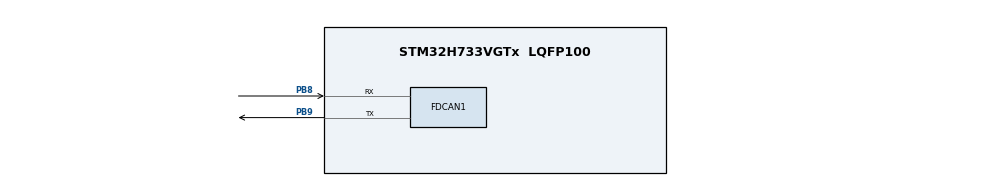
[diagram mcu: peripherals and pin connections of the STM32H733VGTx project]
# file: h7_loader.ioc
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CORTEX_M7.default_mode_Activation=0
CRC.InputDataFormat=CRC_INPUTDATA_FORMAT_WORDS
FDCAN1.AutoRetransmission=ENABLE
FDCAN1.CalculateBaudRateNominal=500000
FDCAN1.CalculateTimeBitNominal=2000
FDCAN1.CalculateTimeQuantumNominal=125.0
FDCAN1.NominalPrescaler=6
FDCAN1.NominalSyncJumpWidth=4
FDCAN1.NominalTimeSeg1=13
FDCAN1.RxFifo0ElmtsNbr=1
FDCAN1.StdFiltersNbr=1
FDCAN1.TxFifoQueueElmtsNbr=1
FREERTOS.Tasks01=defaultTask,24,1024,StartDefaultTask,Default,NULL,Dynamic,NULL,NULL
FREERTOS.configMINIMAL_STACK_SIZE=128
Mcu.Family=STM32H7
Mcu.Name=STM32H733VGTx
Mcu.Package=LQFP100
Mcu.UserConstants=TIM3_PRESCALER,8;ADC_FREQUENCY,1000;TIMx_FREQUENCY,512000000
NVIC.FDCAN1_IT0_IRQn=true\:5\:0\:false\:false\:true\:true\:true\:true\:true
NVIC.FDCAN1_IT1_IRQn=true\:5\:0\:false\:false\:true\:true\:true\:true\:true
NVIC.PriorityGroup=NVIC_PRIORITYGROUP_4
NVIC.TIM6_DAC_IRQn=true\:15\:0\:false\:false\:true\:false\:false\:true\:true
NVIC.TimeBase=TIM6_DAC_IRQn
NVIC.TimeBaseIP=TIM6
PB8.Mode=FDCAN_Activate
PB8.Signal=FDCAN1_RX
PB9.Mode=FDCAN_Activate
PB9.Signal=FDCAN1_TX
PH0-OSC_IN.Mode=HSE-External-Oscillator
PH0-OSC_IN.Signal=RCC_OSC_IN
PH1-OSC_OUT.Mode=HSE-External-Oscillator
PH1-OSC_OUT.Signal=RCC_OSC_OUT
ProjectManager.HeapSize=0x200
ProjectManager.StackSize=0x400
ProjectManager.TargetToolchain=STM32CubeIDE
RCC.ADCFreq_Value=16125000
RCC.APB1Freq_Value=24000000
RCC.APB2Freq_Value=24000000
RCC.APB3Freq_Value=24000000
RCC.APB4Freq_Value=24000000
RCC.CortexFreq_Value=96000000
RCC.D1CPRE=RCC_SYSCLK_DIV2
RCC.D1PPRE=RCC_APB3_DIV2
RCC.D2PPRE1=RCC_APB1_DIV2
RCC.D2PPRE2=RCC_APB2_DIV2
RCC.D3PPRE=RCC_APB4_DIV2
RCC.DIVM1=1
RCC.DIVN1=24
RCC.DIVP1=1
RCC.DIVQ1=4
RCC.HCLKFreq_Value=48000000
RCC.HPRE=RCC_HCLK_DIV2
RCC.HSE_VALUE=8000000
RCC.PLL2FRACN=0
RCC.PLL3FRACN=0
RCC.PLLFRACN=0
RCC.PLLSourceVirtual=RCC_PLLSOURCE_HSE
RCC.SYSCLKFreq_VALUE=192000000
RCC.SYSCLKSource=RCC_SYSCLKSOURCE_PLLCLK
RCC.USBFreq_Value=48000000
VP_CRC_VS_CRC.Mode=CRC_Activate
VP_FREERTOS_VS_CMSIS_V2.Mode=CMSIS_V2
VP_SYS_VS_tim6.Mode=TIM6
board=custom

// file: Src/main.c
/* USER CODE BEGIN Header */
/**
 ******************************************************************************
 * @file           : main.c
 * @brief          : Main program body
 ******************************************************************************
 * @attention
 *
 * Copyright (c) 2024 STMicroelectronics.
 * All rights reserved.
 *
 * This software is licensed under terms that can be found in the LICENSE file
 * in the root directory of this software component.
 * If no LICENSE file comes with this software, it is provided AS-IS.
 *
 ******************************************************************************
 */
/* USER CODE END Header */
#include "main.h"
#include "cmsis_os.h"

/* USER CODE BEGIN Includes */
#include "cmsis_gcc.h"
#include "hw_crc.h"
#include "hw_hal.h"
#include "hw_hardFaultHandler.h"
#include "hw_utils.h"
#include "hw_can.h"

#include "io_can.h"
/* USER CODE END Includes */

/* USER CODE BEGIN PD */
extern uint32_t __app_metadata_start__;
extern uint32_t __app_metadata_size__;

extern uint32_t __app_code_start__;
extern uint32_t __app_code_size__;

extern uint32_t __boot_code_start__;
extern uint32_t __boot_code_size__;

__attribute__((section(".boot_flag"))) uint8_t boot_flag;

typedef enum
{
    LOADER_STATUS_APP_VALID,
    LOADER_STATUS_APP_INVALID,
    LOADER_STATUS_NO_APP
} LoaderStatus;

typedef struct
{
    uint32_t checksum;
    uint32_t size_bytes;
    uint32_t bootloader_status;
} Metadata;
/* USER CODE END PD */

CRC_HandleTypeDef hcrc;

FDCAN_HandleTypeDef hfdcan1;

/* Definitions for defaultTask */
osThreadId_t         defaultTaskHandle;
const osThreadAttr_t defaultTask_attributes = {
    .name       = "defaultTask",
    .stack_size = 1024 * 4,
    .priority   = (osPriority_t)osPriorityNormal,
};
/* USER CODE BEGIN PV */
static void canRxOverflow(uint32_t unused)
{
    UNUSED(unused);
    // BREAK_IF_DEBUGGER_CONNECTED();
}

static void canTxOverflow(uint32_t unused)
{
    UNUSED(unused);
    // BREAK_IF_DEBUGGER_CONNECTED();
}

static const CanConfig can_config = {
    .rx_msg_filter        = NULL,
    .rx_overflow_callback = canRxOverflow,
    .tx_overflow_callback = canTxOverflow,
};

CanHandle can = {
    .can                       = &hfdcan1,
    .can_msg_received_callback = io_can_pushRxMsgToQueue,
};

static LoaderStatus verifyAppCodeChecksum(void)
{
    if (*&__app_code_start__ == 0xFFFFFFFF)
    {
        // If app initial stack pointer is all 0xFF, assume app is not present.
        return LOADER_STATUS_NO_APP;
    }

    Metadata *metadata = (Metadata *)&__app_metadata_start__;
    if (metadata->size_bytes > (uint32_t)&__app_code_size__)
    {
        // App binary size field is invalid.
        return LOADER_STATUS_APP_INVALID;
    }

    uint32_t *buffer              = &__app_code_start__;
    uint32_t  calculated_checksum = hw_crc_calculate(&__app_code_start__, metadata->size_bytes / 4);
    return calculated_checksum == metadata->checksum ? LOADER_STATUS_APP_VALID : LOADER_STATUS_APP_INVALID;
}

_Noreturn static void modifyStackPointerAndJump(const uint32_t *address)
{
    // Disable interrupts before jumping.
    __disable_irq();

    // Disable system tick to stop FreeRTOS timebase.
    SysTick->CTRL = ~SysTick_CTRL_ENABLE_Msk;

    // Clear all pending interrupts by setting all ICPRs (Interrupt Clear Pending Register)
    // to 0xFFFFFFFF. This is done so no interrupts are queued up when we jump to the app.
    // (There are 8 registers on the Cortex-M4)
    for (uint32_t i = 0; i < 8; i++)
    {
        NVIC->ICPR[i] = 0xFFFFFFFF;
    }

    // Update the vector table offset register. When an interrupt is fired,
    // the microcontroller looks for the corresponding interrupt service handler
    // at the memory address in the VTOR. We need to update it so the app ISRs
    // are used.
    SCB->VTOR = (uint32_t)address;

    // Flush processor pipeline.
    __ISB();

    // Tell MCU to use the main stack pointer rather than process stack pointer (PSP is used with RTOS)
    __set_CONTROL(__get_CONTROL() & ~CONTROL_SPSEL_Msk);

    // Modify stack pointer and jump to code.
    // In a binary built with our linker settings, the interrupt vector table is the first thing
    // placed in flash. The first word of the vector table contains the initial stack pointer
    // and the second word containers the address of the reset handler. Update stack pointer and
    // program counter accordingly.
#pragma GCC diagnostic push
#pragma GCC diagnostic ignored "-Warray-bounds"
    uint32_t newStackPointer = address[0];
    uint32_t resetHandler    = address[1];
#pragma GCC diagnostic pop
    __set_MSP(newStackPointer);
    void (*app_reset_handler)(void) = (void (*)(void))resetHandler;
    app_reset_handler(); // Call app's Reset_Handler, starting the app.

    // Should never get here!
    BREAK_IF_DEBUGGER_CONNECTED();
    for (;;)
    {
    }
}
/* USER CODE END PV */

void        SystemClock_Config(void);
static void MX_GPIO_Init(void);
static void MX_CRC_Init(void);
static void MX_FDCAN1_Init(void);
void        StartDefaultTask(void *argument);

int main(void)
{
    /* USER CODE BEGIN 1 */
    // SEGGER_SYSVIEW_Conf();
    /* USER CODE END 1 */

    /* MCU Configuration--------------------------------------------------------*/

    /* Reset of all peripherals, Initializes the Flash interface and the Systick. */
    HAL_Init();

    /* Configure the system clock */
    SystemClock_Config();

    /* USER CODE BEGIN SysInit */
    __HAL_RCC_CRC_CLK_ENABLE();
    __HAL_RCC_FDCAN_CLK_ENABLE();
    /* USER CODE END SysInit */

    /* Initialize all configured peripherals */
    MX_GPIO_Init();
    MX_CRC_Init();
    MX_FDCAN1_Init();
    /* USER CODE BEGIN 2 */

    hw_hardFaultHandler_init();
    hw_crc_init(&hcrc);
    io_can_init(&can_config);
    hw_can_init(&can);

    LoaderStatus status = verifyAppCodeChecksum();
    HAL_CRC_DeInit(&hcrc);
    if (status == LOADER_STATUS_APP_INVALID || boot_flag == 0x01)
    {
        modifyStackPointerAndJump(&__boot_code_start__);
    }
    else
    {
        modifyStackPointerAndJump(&__app_code_start__);
    }
    /* USER CODE END 2 */

    /* Init scheduler */
    osKernelInitialize();

    /* Create the thread(s) */
    /* creation of defaultTask */
    defaultTaskHandle = osThreadNew(StartDefaultTask, NULL, &defaultTask_attributes);

    /* Start scheduler */
    osKernelStart();

    /* We should never get here as control is now taken by the scheduler */
    /* Infinite loop */
    while (1)
    {

    }
}

void SystemClock_Config(void)
{
    RCC_OscInitTypeDef RCC_OscInitStruct = { 0 };
    RCC_ClkInitTypeDef RCC_ClkInitStruct = { 0 };

    /** Supply configuration update enable
     */
    HAL_PWREx_ConfigSupply(PWR_LDO_SUPPLY);

    /** Configure the main internal regulator output voltage
     */
    __HAL_PWR_VOLTAGESCALING_CONFIG(PWR_REGULATOR_VOLTAGE_SCALE3);

    while (!__HAL_PWR_GET_FLAG(PWR_FLAG_VOSRDY))
    {
    }

    /** Initializes the RCC Oscillators according to the specified parameters
     * in the RCC_OscInitTypeDef structure.
     */
    RCC_OscInitStruct.OscillatorType = RCC_OSCILLATORTYPE_HSE;
    RCC_OscInitStruct.HSEState       = RCC_HSE_ON;
    RCC_OscInitStruct.PLL.PLLState   = RCC_PLL_ON;
    RCC_OscInitStruct.PLL.PLLSource  = RCC_PLLSOURCE_HSE;
    RCC_OscInitStruct.PLL.PLLM       = 1;
    RCC_OscInitStruct.PLL.PLLN       = 24;
    RCC_OscInitStruct.PLL.PLLP       = 1;
    RCC_OscInitStruct.PLL.PLLQ       = 4;
    RCC_OscInitStruct.PLL.PLLR       = 2;
    RCC_OscInitStruct.PLL.PLLRGE     = RCC_PLL1VCIRANGE_3;
    RCC_OscInitStruct.PLL.PLLVCOSEL  = RCC_PLL1VCOWIDE;
    RCC_OscInitStruct.PLL.PLLFRACN   = 0;
    if (HAL_RCC_OscConfig(&RCC_OscInitStruct) != HAL_OK)
    {
        Error_Handler();
    }

    /** Initializes the CPU, AHB and APB buses clocks
     */
    RCC_ClkInitStruct.ClockType = RCC_CLOCKTYPE_HCLK | RCC_CLOCKTYPE_SYSCLK | RCC_CLOCKTYPE_PCLK1 |
                                  RCC_CLOCKTYPE_PCLK2 | RCC_CLOCKTYPE_D3PCLK1 | RCC_CLOCKTYPE_D1PCLK1;
    RCC_ClkInitStruct.SYSCLKSource   = RCC_SYSCLKSOURCE_PLLCLK;
    RCC_ClkInitStruct.SYSCLKDivider  = RCC_SYSCLK_DIV2;
    RCC_ClkInitStruct.AHBCLKDivider  = RCC_HCLK_DIV2;
    RCC_ClkInitStruct.APB3CLKDivider = RCC_APB3_DIV2;
    RCC_ClkInitStruct.APB1CLKDivider = RCC_APB1_DIV2;
    RCC_ClkInitStruct.APB2CLKDivider = RCC_APB2_DIV2;
    RCC_ClkInitStruct.APB4CLKDivider = RCC_APB4_DIV2;

    if (HAL_RCC_ClockConfig(&RCC_ClkInitStruct, FLASH_LATENCY_1) != HAL_OK)
    {
        Error_Handler();
    }
}

static void MX_CRC_Init(void)
{

    hcrc.Instance                     = CRC;
    hcrc.Init.DefaultPolynomialUse    = DEFAULT_POLYNOMIAL_ENABLE;
    hcrc.Init.DefaultInitValueUse     = DEFAULT_INIT_VALUE_ENABLE;
    hcrc.Init.InputDataInversionMode  = CRC_INPUTDATA_INVERSION_NONE;
    hcrc.Init.OutputDataInversionMode = CRC_OUTPUTDATA_INVERSION_DISABLE;
    hcrc.InputDataFormat              = CRC_INPUTDATA_FORMAT_WORDS;
    if (HAL_CRC_Init(&hcrc) != HAL_OK)
    {
        Error_Handler();
    }
    /* USER CODE BEGIN CRC_Init 2 */
    uint32_t test_data[] = { 0x12345678, 0x9ABCDEF0 };
    size_t   test_length = sizeof(test_data) / sizeof(test_data[0]);
    uint32_t test_crc    = HAL_CRC_Calculate(&hcrc, test_data, test_length);
    /* USER CODE END CRC_Init 2 */
}

static void MX_FDCAN1_Init(void)
{

    hfdcan1.Instance                  = FDCAN1;
    hfdcan1.Init.FrameFormat          = FDCAN_FRAME_CLASSIC;
    hfdcan1.Init.Mode                 = FDCAN_MODE_NORMAL;
    hfdcan1.Init.AutoRetransmission   = ENABLE;
    hfdcan1.Init.TransmitPause        = DISABLE;
    hfdcan1.Init.ProtocolException    = DISABLE;
    hfdcan1.Init.NominalPrescaler     = 6;
    hfdcan1.Init.NominalSyncJumpWidth = 4;
    hfdcan1.Init.NominalTimeSeg1      = 13;
    hfdcan1.Init.NominalTimeSeg2      = 2;
    hfdcan1.Init.DataPrescaler        = 1;
    hfdcan1.Init.DataSyncJumpWidth    = 1;
    hfdcan1.Init.DataTimeSeg1         = 1;
    hfdcan1.Init.DataTimeSeg2         = 1;
    hfdcan1.Init.MessageRAMOffset     = 0;
    hfdcan1.Init.StdFiltersNbr        = 1;
    hfdcan1.Init.ExtFiltersNbr        = 0;
    hfdcan1.Init.RxFifo0ElmtsNbr      = 1;
    hfdcan1.Init.RxFifo0ElmtSize      = FDCAN_DATA_BYTES_8;
    hfdcan1.Init.RxFifo1ElmtsNbr      = 0;
    hfdcan1.Init.RxFifo1ElmtSize      = FDCAN_DATA_BYTES_8;
    hfdcan1.Init.RxBuffersNbr         = 0;
    hfdcan1.Init.RxBufferSize         = FDCAN_DATA_BYTES_8;
    hfdcan1.Init.TxEventsNbr          = 0;
    hfdcan1.Init.TxBuffersNbr         = 0;
    hfdcan1.Init.TxFifoQueueElmtsNbr  = 1;
    hfdcan1.Init.TxFifoQueueMode      = FDCAN_TX_FIFO_OPERATION;
    hfdcan1.Init.TxElmtSize           = FDCAN_DATA_BYTES_8;
    if (HAL_FDCAN_Init(&hfdcan1) != HAL_OK)
    {
        Error_Handler();
    }
}

static void MX_GPIO_Init(void)
{

    /* GPIO Ports Clock Enable */
    __HAL_RCC_GPIOH_CLK_ENABLE();
    __HAL_RCC_GPIOB_CLK_ENABLE();

}

void StartDefaultTask(void *argument)
{
}

void HAL_TIM_PeriodElapsedCallback(TIM_HandleTypeDef *htim)
{
    if (htim->Instance == TIM6)
    {
        HAL_IncTick();
    }
}

void Error_Handler(void)
{
    __disable_irq();
    while (1)
    {
    }
}
